# PIC32MK0128MCA032 register map
Vendor: Microchip
Registers are 32-bit, read-write, reset 0x0 unless marked. A register's access mark holds for its fields unless they carry their own. Addresses are absolute, and some are shared; only a register's first bit layout is shown; [hi:lo] are bit positions; {n}, {i} and the like mark numbered series; 'fields as' and 'values as' point back to an identical list.

## PORTB
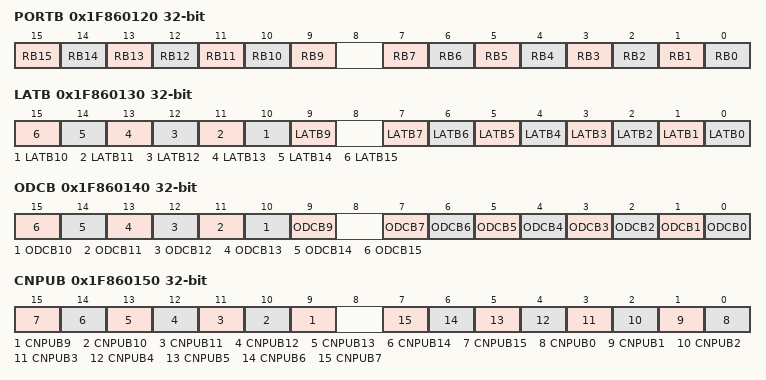
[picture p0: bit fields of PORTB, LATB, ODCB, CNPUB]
0x1F860120 PORTB reset not defined — (power-on value ----------------xxxxxxx-xxxxxxxx)
  [n] RB{n} (n=9..15), [n] RB{n} (n=0..7)
0x1F860130 LATB reset not defined — (power-on value ----------------xxxxxxx-xxxxxxxx)
  [n] LATB{n} (n=9..15), [n] LATB{n} (n=0..7)
0x1F860140 ODCB
  [n] ODCB{n} (n=9..15), [n] ODCB{n} (n=0..7)
0x1F860150 CNPUB
  [n] CNPUB{n} (n=9..15), [n] CNPUB{n} (n=0..7)
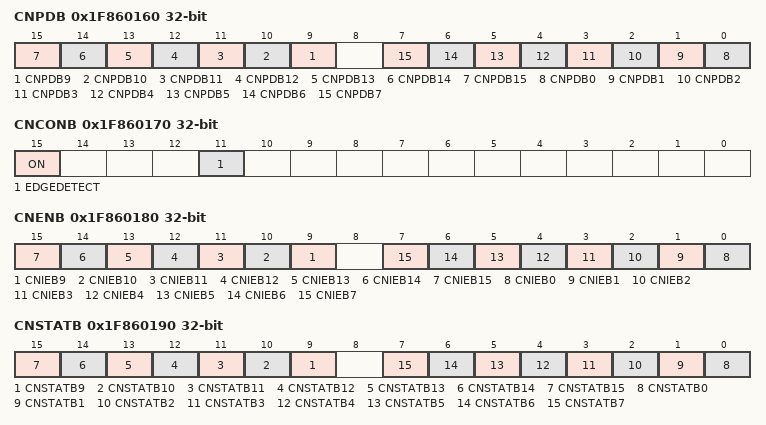
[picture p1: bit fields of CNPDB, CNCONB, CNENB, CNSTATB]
0x1F860160 CNPDB
  [n] CNPDB{n} (n=9..15), [n] CNPDB{n} (n=0..7)
0x1F860170 CNCONB
  [15] ON, [11] EDGEDETECT
0x1F860180 CNENB
  [n] CNIEB{n} (n=9..15), [n] CNIEB{n} (n=0..7)
0x1F860190 CNSTATB
  [n] CNSTATB{n} (n=9..15), [n] CNSTATB{n} (n=0..7)
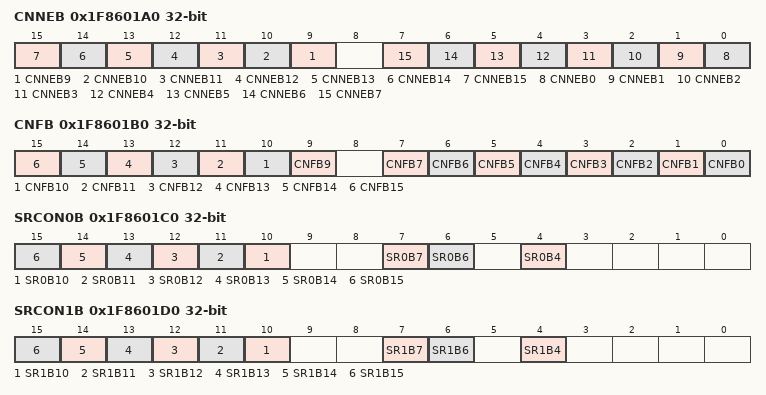
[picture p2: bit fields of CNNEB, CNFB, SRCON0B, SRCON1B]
0x1F8601A0 CNNEB
  [n] CNNEB{n} (n=9..15), [n] CNNEB{n} (n=0..7)
0x1F8601B0 CNFB
  [n] CNFB{n} (n=9..15), [n] CNFB{n} (n=0..7)
0x1F8601C0 SRCON0B
  [n] SR0B{n} (n=10..15), [7] SR0B7, [6] SR0B6, [4] SR0B4
0x1F8601D0 SRCON1B
  [n] SR1B{n} (n=10..15), [7] SR1B7, [6] SR1B6, [4] SR1B4

## PORTC
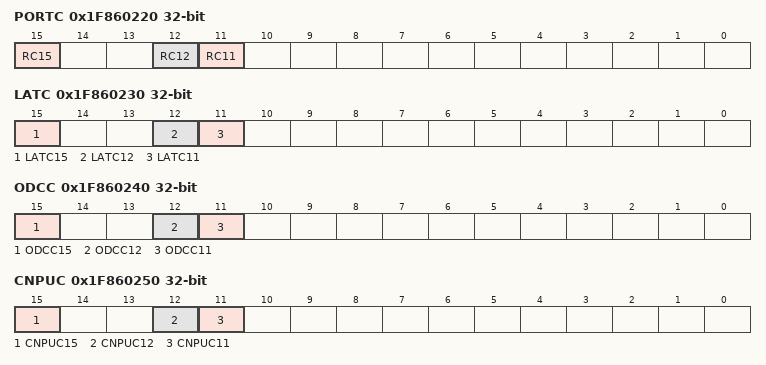
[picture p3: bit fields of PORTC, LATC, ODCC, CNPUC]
0x1F860220 PORTC reset not defined — (power-on value ----------------x--xx-----------)
  [15] RC15, [12] RC12, [11] RC11
0x1F860230 LATC reset not defined — (power-on value ----------------x--xx-----------)
  [15] LATC15, [12] LATC12, [11] LATC11
0x1F860240 ODCC
  [15] ODCC15, [12] ODCC12, [11] ODCC11
0x1F860250 CNPUC
  [15] CNPUC15, [12] CNPUC12, [11] CNPUC11
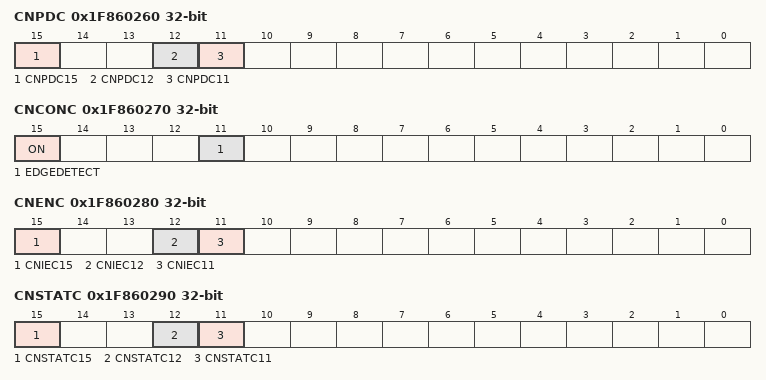
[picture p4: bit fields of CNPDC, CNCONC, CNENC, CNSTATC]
0x1F860260 CNPDC
  [15] CNPDC15, [12] CNPDC12, [11] CNPDC11
0x1F860270 CNCONC
  [15] ON, [11] EDGEDETECT
0x1F860280 CNENC
  [15] CNIEC15, [12] CNIEC12, [11] CNIEC11
0x1F860290 CNSTATC
  [15] CNSTATC15, [12] CNSTATC12, [11] CNSTATC11
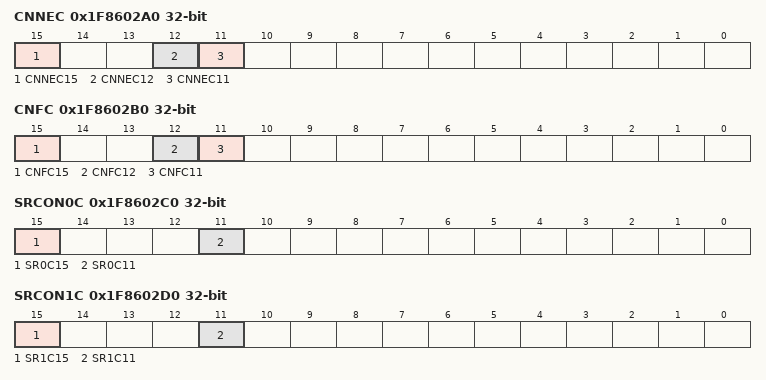
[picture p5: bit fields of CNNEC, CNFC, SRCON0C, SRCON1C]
0x1F8602A0 CNNEC
  [15] CNNEC15, [12] CNNEC12, [11] CNNEC11
0x1F8602B0 CNFC
  [15] CNFC15, [12] CNFC12, [11] CNFC11
0x1F8602C0 SRCON0C
  [15] SR0C15, [11] SR0C11
0x1F8602D0 SRCON1C
  [15] SR1C15, [11] SR1C11

## PORTD
0x1F860320 PORTD access not given reset not defined
0x1F860330 LATD access not given reset not defined
0x1F860340 ODCD access not given reset not defined
0x1F860360 CNPDD access not given reset not defined
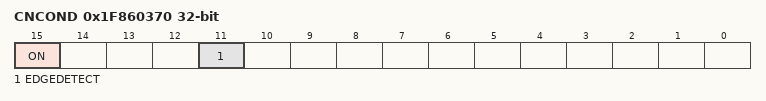
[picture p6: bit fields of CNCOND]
0x1F860370 CNCOND
  [15] ON, [11] EDGEDETECT
0x1F860380 CNEND access not given reset not defined
0x1F860390 CNSTATD access not given reset not defined
0x1F8603A0 CNNED access not given reset not defined
0x1F8603B0 CNFD access not given reset not defined
0x1F8603C0 SRCON0D access not given reset not defined
0x1F8603D0 SRCON1D access not given reset not defined

## RTCC
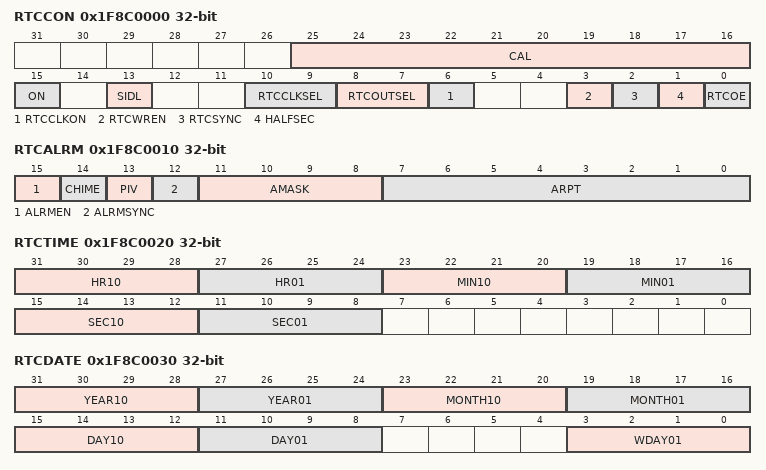
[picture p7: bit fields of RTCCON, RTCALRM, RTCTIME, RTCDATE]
0x1F8C0000 RTCCON
  [25:16] CAL, [15] ON, [13] SIDL, [10:9] RTCCLKSEL, [8:7] RTCOUTSEL, [6] RTCCLKON, [3] RTCWREN, [2] RTCSYNC ro, [1] HALFSEC ro, [0] RTCOE
0x1F8C0010 RTCALRM
  [15] ALRMEN, [14] CHIME, [13] PIV, [12] ALRMSYNC, [11:8] AMASK, [7:0] ARPT
0x1F8C0020 RTCTIME reset not defined — (power-on value 000xxxxxxxxxxxxx0xxxxxxx--------)
  [31:28] HR10, [27:24] HR01, [23:20] MIN10, [19:16] MIN01, [15:12] SEC10, [11:8] SEC01
0x1F8C0030 RTCDATE reset not defined — (power-on value xxxxxxxx000xxxxx00xxxxxx----0xxx)
  [31:28] YEAR10, [27:24] YEAR01, [23:20] MONTH10, [19:16] MONTH01, [15:12] DAY10, [11:8] DAY01, [3:0] WDAY01
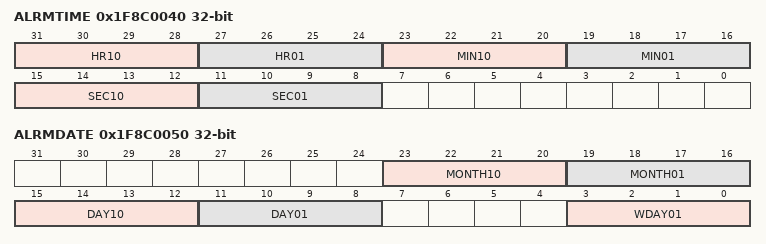
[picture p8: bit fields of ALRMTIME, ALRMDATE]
0x1F8C0040 ALRMTIME reset not defined — (power-on value 000xxxxx0xxxxxxx0xxxxxxx--------)
  fields as RTCTIME
0x1F8C0050 ALRMDATE reset not defined — (power-on value --------000xxxxx00xxxxxx----0xxx)
  [23:20] MONTH10, [19:16] MONTH01, [15:12] DAY10, [11:8] DAY01, [3:0] WDAY01

## SB
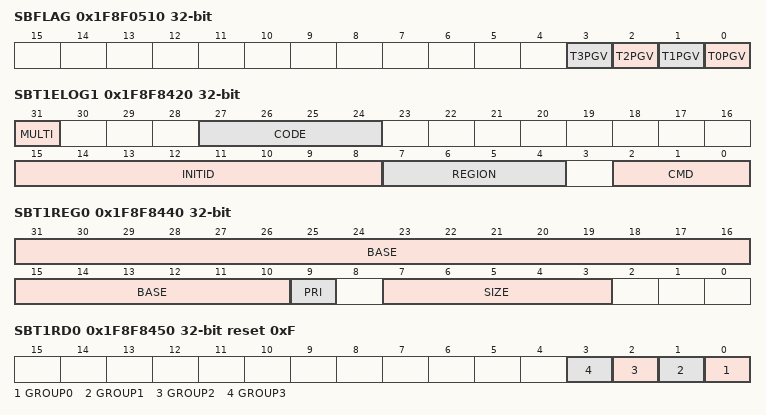
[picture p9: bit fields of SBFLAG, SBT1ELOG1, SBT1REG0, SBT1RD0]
0x1F8F0510 SBFLAG ro
  [n] T{n}PGV (n=0..3)
0x1F8F8420 SBT1ELOG1
  [31] MULTI, [27:24] CODE, [15:8] INITID ro, [7:4] REGION ro, [2:0] CMD ro
0x1F8F8424 SBT1ELOG2 ro
  [1:0] GROUP
0x1F8F8428 SBT1ECON
  [24] ERRP
0x1F8F8430 SBT1ECLRS ro
  [0] CLEAR
0x1F8F8438 SBT1ECLRM ro
  [0] CLEAR
0x1F8F8440 SBT1REG0 reset not defined — (power-on value 0000000000000000000000x-00000---)
  [31:10] BASE, [9] PRI ro, [7:3] SIZE
0x1F8F8450 SBT1RD0 reset 0xF
  [n] GROUP{n} (n=0..3)
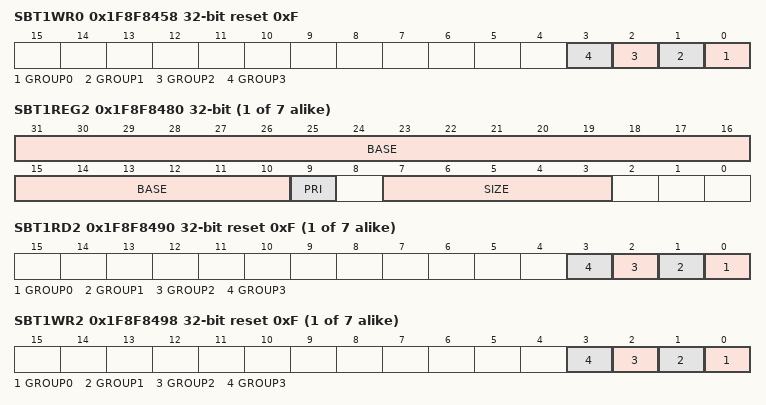
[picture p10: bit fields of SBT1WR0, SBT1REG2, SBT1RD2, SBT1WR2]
0x1F8F8458 SBT1WR0 reset 0xF
  [n] GROUP{n} (n=0..3)
{0x1F8F8440+0x20*i} SBT1REG{i} reset not defined (i=2..8) — (power-on value 0000000000000000000000x-00000---)
  [31:10] BASE, [9] PRI ro, [7:3] SIZE
{0x1F8F8450+0x20*i} SBT1RD{i} reset 0xF (i=2..8)
  [n] GROUP{n} (n=0..3)
{0x1F8F8458+0x20*i} SBT1WR{i} reset 0xF (i=2..8)
  [n] GROUP{n} (n=0..3)

## DOS_EIP_00136_ssx
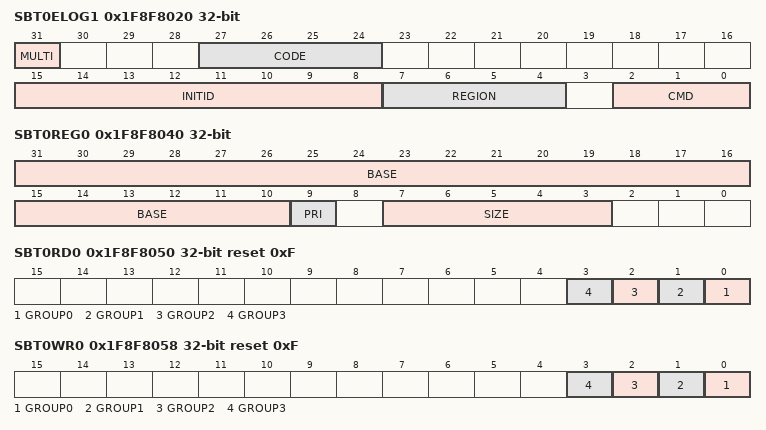
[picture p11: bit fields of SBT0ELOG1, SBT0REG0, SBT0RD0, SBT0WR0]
0x1F8F8020 SBT0ELOG1
  [31] MULTI, [27:24] CODE, [15:8] INITID ro, [7:4] REGION ro, [2:0] CMD ro
0x1F8F8024 SBT0ELOG2 ro
  [1:0] GROUP
0x1F8F8028 SBT0ECON
  [24] ERRP
0x1F8F8030 SBT0ECLRS ro
  [0] CLEAR
0x1F8F8038 SBT0ECLRM ro
  [0] CLEAR
0x1F8F8040 SBT0REG0 reset not defined — (power-on value 0000000000000000000000x-00000---)
  [31:10] BASE, [9] PRI ro, [7:3] SIZE
0x1F8F8050 SBT0RD0 reset 0xF
  [n] GROUP{n} (n=0..3)
0x1F8F8058 SBT0WR0 reset 0xF
  [n] GROUP{n} (n=0..3)
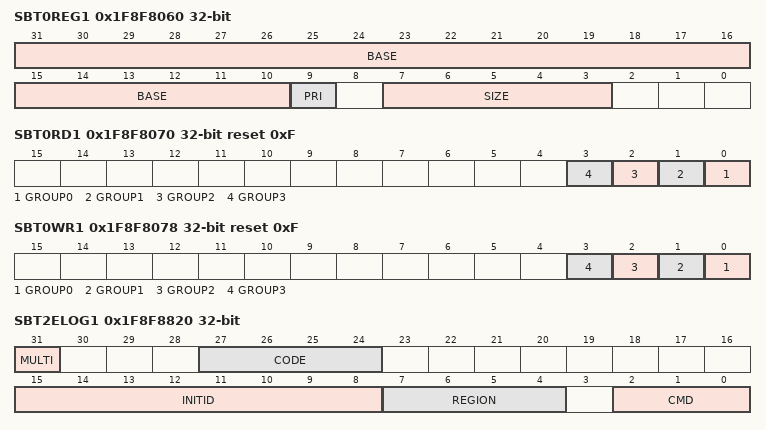
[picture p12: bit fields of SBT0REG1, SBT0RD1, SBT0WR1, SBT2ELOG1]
0x1F8F8060 SBT0REG1 reset not defined — (power-on value 0000000000000000000000x-00000---)
  [31:10] BASE, [9] PRI ro, [7:3] SIZE
0x1F8F8070 SBT0RD1 reset 0xF
  [n] GROUP{n} (n=0..3)
0x1F8F8078 SBT0WR1 reset 0xF
  [n] GROUP{n} (n=0..3)
0x1F8F8820 SBT2ELOG1
  fields as SBT0ELOG1
0x1F8F8824 SBT2ELOG2 ro
  [1:0] GROUP
0x1F8F8828 SBT2ECON
  [24] ERRP
0x1F8F8830 SBT2ECLRS ro
  [0] CLEAR
0x1F8F8838 SBT2ECLRM ro
  [0] CLEAR
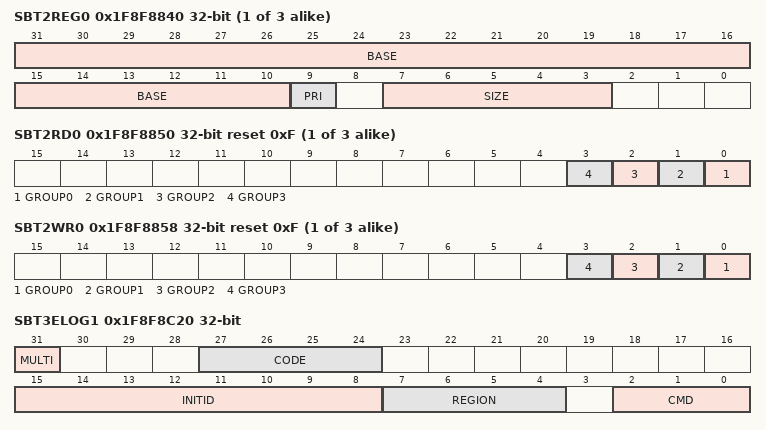
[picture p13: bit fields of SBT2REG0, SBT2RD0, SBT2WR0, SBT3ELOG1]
{0x1F8F8840+0x20*i} SBT2REG{i} reset not defined (i=0..2) — (power-on value 0000000000000000000000x-00000---)
  [31:10] BASE, [9] PRI ro, [7:3] SIZE
{0x1F8F8850+0x20*i} SBT2RD{i} reset 0xF (i=0..2)
  [n] GROUP{n} (n=0..3)
{0x1F8F8858+0x20*i} SBT2WR{i} reset 0xF (i=0..2)
  [n] GROUP{n} (n=0..3)
0x1F8F8C20 SBT3ELOG1
  fields as SBT0ELOG1
0x1F8F8C24 SBT3ELOG2 ro
  [1:0] GROUP
0x1F8F8C28 SBT3ECON
  [24] ERRP
0x1F8F8C30 SBT3ECLRS ro
  [0] CLEAR
0x1F8F8C38 SBT3ECLRM ro
  [0] CLEAR
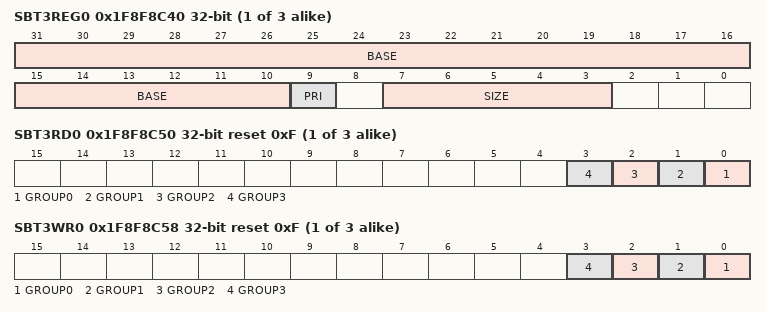
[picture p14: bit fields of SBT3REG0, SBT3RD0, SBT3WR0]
{0x1F8F8C40+0x20*i} SBT3REG{i} reset not defined (i=0..2) — (power-on value 0000000000000000000000x-00000---)
  [31:10] BASE, [9] PRI ro, [7:3] SIZE
{0x1F8F8C50+0x20*i} SBT3RD{i} reset 0xF (i=0..2)
  [n] GROUP{n} (n=0..3)
{0x1F8F8C58+0x20*i} SBT3WR{i} reset 0xF (i=0..2)
  [n] GROUP{n} (n=0..3)
